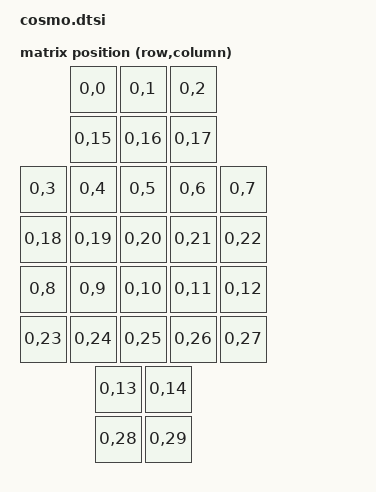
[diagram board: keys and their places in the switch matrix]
// This file was generated from a template. Edit it to match your keyboard.
// See https://zmk.dev/docs/development/hardware-integration/new-shield for more
// instructions.

#include <dt-bindings/zmk/matrix_transform.h>

#include "cosmo-layouts.dtsi"

/ {
    chosen {
        zmk,physical-layout = &default_layout;
    };

    kscan: kscan {
        // If the hardware does not use a switch matrix, change this to the
        // appropriate driver and update the properties below to match.
        // See https://zmk.dev/docs/config/kscan for supported key scan drivers.
        compatible = "zmk,kscan-gpio-direct";
        // Set this to "col2row" or "row2col" to match the hardware. If using
        // "row2col", change the col-gpios in the _left.overlay and _right.overlay
        // files to (GPIO_ACTIVE_HIGH | GPIO_PULL_DOWN) and the row-gpios here to
        // GPIO_ACTIVE_HIGH.
        //diode-direction = "col2row";
        wakeup-source;

        // Replace these comments with the GPIO pins in the matrix.
        // See https://zmk.dev/docs/development/hardware-integration/new-shield#shield-overlays
        //row-gpios = <&pro_micro 0 (GPIO_ACTIVE_HIGH | GPIO_PULL_DOWN)> ;
    };

    default_transform: default_transform {
        // See https://zmk.dev/docs/development/hardware-integration/new-shield#matrix-transform
        // for how to configure this
        compatible = "zmk,matrix-transform";
        columns = <10>;
        rows = <4>;

        map = <
                    RC(0, 0) RC(0, 1) RC(0, 2) 
                    RC(0, 15) RC(0, 16) RC(0, 17) 
                    RC(0, 3) RC(0, 4) RC(0, 5) RC(0, 6) RC(0,7)
                    RC(0, 18) RC(0, 19) RC(0, 20) RC(0, 21) RC(0,22)
                    RC(0, 8) RC(0, 9) RC(0, 10) RC(0, 11) RC(0,12)
                    RC(0, 23) RC(0, 24) RC(0, 25) RC(0, 26) RC(0,27)
                    RC(0, 13) RC(0, 14) 
                    RC(0, 28) RC(0, 29)
        >;
    };
};
